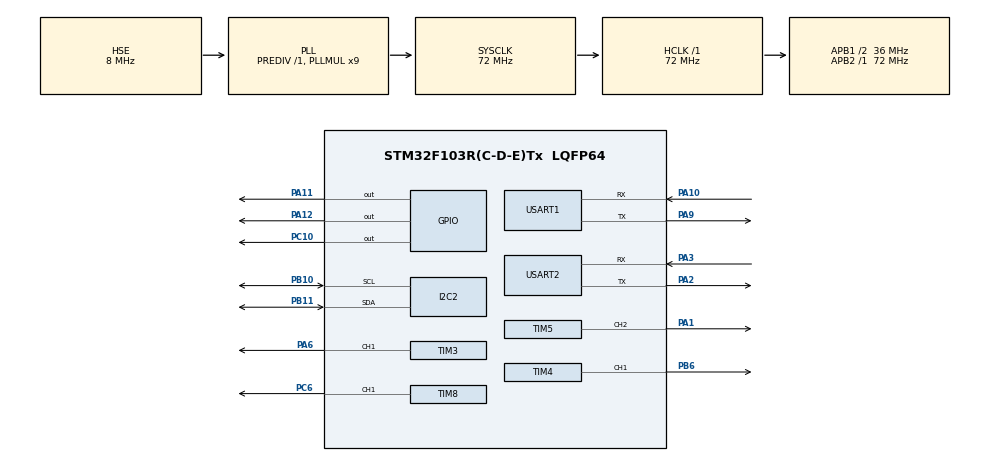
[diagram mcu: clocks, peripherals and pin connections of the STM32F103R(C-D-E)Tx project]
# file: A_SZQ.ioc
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Dma.Request0=USART1_RX
Dma.Request1=USART1_TX
Dma.USART1_RX.0.Direction=DMA_PERIPH_TO_MEMORY
Dma.USART1_RX.0.Instance=DMA1_Channel5
Dma.USART1_RX.0.MemDataAlignment=DMA_MDATAALIGN_BYTE
Dma.USART1_RX.0.MemInc=DMA_MINC_ENABLE
Dma.USART1_RX.0.Mode=DMA_NORMAL
Dma.USART1_RX.0.PeriphDataAlignment=DMA_PDATAALIGN_BYTE
Dma.USART1_RX.0.PeriphInc=DMA_PINC_DISABLE
Dma.USART1_RX.0.Priority=DMA_PRIORITY_LOW
Dma.USART1_TX.1.Direction=DMA_MEMORY_TO_PERIPH
Dma.USART1_TX.1.Instance=DMA1_Channel4
Dma.USART1_TX.1.MemDataAlignment=DMA_MDATAALIGN_BYTE
Dma.USART1_TX.1.MemInc=DMA_MINC_ENABLE
Dma.USART1_TX.1.Mode=DMA_NORMAL
Dma.USART1_TX.1.PeriphDataAlignment=DMA_PDATAALIGN_BYTE
Dma.USART1_TX.1.PeriphInc=DMA_PINC_DISABLE
Dma.USART1_TX.1.Priority=DMA_PRIORITY_LOW
I2C2.I2C_Mode=I2C_Fast
Mcu.Family=STM32F1
Mcu.Name=STM32F103R(C-D-E)Tx
Mcu.Package=LQFP64
NVIC.DMA1_Channel4_IRQn=true\:0\:0\:false\:false\:true\:false\:true\:true
NVIC.DMA1_Channel5_IRQn=true\:0\:0\:false\:false\:true\:false\:true\:true
NVIC.PriorityGroup=NVIC_PRIORITYGROUP_4
NVIC.TIM3_IRQn=true\:0\:0\:false\:false\:true\:true\:true\:true
NVIC.TIM4_IRQn=true\:0\:0\:false\:false\:true\:true\:true\:true
NVIC.TIM8_BRK_IRQn=true\:0\:0\:false\:false\:true\:true\:true\:true
NVIC.TIM8_CC_IRQn=true\:0\:0\:false\:false\:true\:true\:true\:true
NVIC.TIM8_TRG_COM_IRQn=true\:0\:0\:false\:false\:true\:true\:true\:true
NVIC.TIM8_UP_IRQn=true\:0\:0\:false\:false\:true\:true\:true\:true
NVIC.USART1_IRQn=true\:0\:0\:false\:false\:true\:true\:true\:true
PA1.Signal=S_TIM5_CH2
PA10.Mode=Asynchronous
PA10.Signal=USART1_RX
PA11.Signal=GPIO_Output
PA12.Signal=GPIO_Output
PA13.Mode=Serial_Wire
PA13.Signal=SYS_JTMS-SWDIO
PA14.Mode=Serial_Wire
PA14.Signal=SYS_JTCK-SWCLK
PA2.Mode=Asynchronous
PA2.Signal=USART2_TX
PA3.Mode=Asynchronous
PA3.Signal=USART2_RX
PA6.Signal=S_TIM3_CH1
PA9.Mode=Asynchronous
PA9.Signal=USART1_TX
PB10.Mode=I2C
PB10.Signal=I2C2_SCL
PB11.Mode=I2C
PB11.Signal=I2C2_SDA
PB6.Signal=S_TIM4_CH1
PC10.Signal=GPIO_Output
PC6.Signal=S_TIM8_CH1
PD0-OSC_IN.Mode=HSE-External-Oscillator
PD0-OSC_IN.Signal=RCC_OSC_IN
PD1-OSC_OUT.Mode=HSE-External-Oscillator
PD1-OSC_OUT.Signal=RCC_OSC_OUT
ProjectManager.HeapSize=0x200
ProjectManager.StackSize=0x400
ProjectManager.TargetToolchain=MDK-ARM V5.32
RCC.AHBFreq_Value=72000000
RCC.APB1CLKDivider=RCC_HCLK_DIV2
RCC.APB1Freq_Value=36000000
RCC.APB1TimFreq_Value=72000000
RCC.APB2Freq_Value=72000000
RCC.APB2TimFreq_Value=72000000
RCC.HCLKFreq_Value=72000000
RCC.PLLMUL=RCC_PLL_MUL9
RCC.PLLSourceVirtual=RCC_PLLSOURCE_HSE
RCC.SYSCLKFreq_VALUE=72000000
RCC.SYSCLKSource=RCC_SYSCLKSOURCE_PLLCLK
RCC.USBFreq_Value=72000000
SH.S_TIM3_CH1.0=TIM3_CH1,PWM Generation1 CH1
SH.S_TIM4_CH1.0=TIM4_CH1,PWM Generation1 CH1
SH.S_TIM5_CH2.0=TIM5_CH2,PWM Generation2 CH2
SH.S_TIM8_CH1.0=TIM8_CH1,PWM Generation1 CH1
TIM3.Channel-PWM\ Generation1\ CH1=TIM_CHANNEL_1
TIM3.Period=100-1
TIM3.Prescaler=720-1
TIM4.AutoReloadPreload=TIM_AUTORELOAD_PRELOAD_ENABLE
TIM4.Channel-PWM\ Generation1\ CH1=TIM_CHANNEL_1
TIM4.Period=100-1
TIM4.Prescaler=720-1
TIM5.AutoReloadPreload=TIM_AUTORELOAD_PRELOAD_ENABLE
TIM5.Channel-PWM\ Generation2\ CH2=TIM_CHANNEL_2
TIM5.Period=2000-1
TIM5.Prescaler=720-1
TIM8.Channel-PWM\ Generation1\ CH1=TIM_CHANNEL_1
TIM8.Period=100-1
TIM8.Prescaler=720-1
USART1.VirtualMode=VM_ASYNC
USART2.VirtualMode=VM_ASYNC
VP_TIM3_VS_ClockSourceINT.Mode=Internal
VP_TIM4_VS_ClockSourceINT.Mode=Internal
VP_TIM5_VS_ClockSourceINT.Mode=Internal
VP_TIM8_VS_ClockSourceINT.Mode=Internal
board=custom

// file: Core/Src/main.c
/* USER CODE BEGIN Header */
/**
  ******************************************************************************
  * @file           : main.c
  * @brief          : Main program body
  ******************************************************************************
  * @attention
  *
  * Copyright (c) 2025 STMicroelectronics.
  * All rights reserved.
  *
  * This software is licensed under terms that can be found in the LICENSE file
  * in the root directory of this software component.
  * If no LICENSE file comes with this software, it is provided AS-IS.
  *
  ******************************************************************************
  */
/* USER CODE END Header */
#include "main.h"
#include "dma.h"
#include "i2c.h"
#include "tim.h"
#include "usart.h"
#include "gpio.h"

/* USER CODE BEGIN Includes */
#include "headfile.h"

/* USER CODE END Includes */

void SystemClock_Config(void);

int main(void)
{

  /* MCU Configuration--------------------------------------------------------*/

  /* Reset of all peripherals, Initializes the Flash interface and the Systick. */
  HAL_Init();

  /* Configure the system clock */
  SystemClock_Config();

  /* Initialize all configured peripherals */
  MX_GPIO_Init();
  MX_DMA_Init();
  MX_I2C2_Init();
  MX_TIM4_Init();
  MX_USART1_UART_Init();
  MX_USART2_UART_Init();
  MX_TIM3_Init();
  MX_TIM8_Init();
  MX_TIM5_Init();
  /* USER CODE BEGIN 2 */

Usart1_init();
Usart1_ReadData();
OLED_Init();
HAL_TIM_PWM_Start(&htim5, TIM_CHANNEL_2);
BJMotor_Speed(40,25);

  /* USER CODE END 2 */

  /* Infinite loop */
  /* USER CODE BEGIN WHILE */
  while (1)
  {
    lcd_show();

//char text[20];
//      sprintf(text,"12333");
//      Usart1_SendData((uint8_t *)text,3);
      HAL_Delay(400);
    user_uart_process();
    /* USER CODE END WHILE */

  }
}

void SystemClock_Config(void)
{
  RCC_OscInitTypeDef RCC_OscInitStruct = {0};
  RCC_ClkInitTypeDef RCC_ClkInitStruct = {0};

  /** Initializes the RCC Oscillators according to the specified parameters
  * in the RCC_OscInitTypeDef structure.
  */
  RCC_OscInitStruct.OscillatorType = RCC_OSCILLATORTYPE_HSE;
  RCC_OscInitStruct.HSEState = RCC_HSE_ON;
  RCC_OscInitStruct.HSEPredivValue = RCC_HSE_PREDIV_DIV1;
  RCC_OscInitStruct.HSIState = RCC_HSI_ON;
  RCC_OscInitStruct.PLL.PLLState = RCC_PLL_ON;
  RCC_OscInitStruct.PLL.PLLSource = RCC_PLLSOURCE_HSE;
  RCC_OscInitStruct.PLL.PLLMUL = RCC_PLL_MUL9;
  if (HAL_RCC_OscConfig(&RCC_OscInitStruct) != HAL_OK)
  {
    Error_Handler();
  }

  /** Initializes the CPU, AHB and APB buses clocks
  */
  RCC_ClkInitStruct.ClockType = RCC_CLOCKTYPE_HCLK|RCC_CLOCKTYPE_SYSCLK
                              |RCC_CLOCKTYPE_PCLK1|RCC_CLOCKTYPE_PCLK2;
  RCC_ClkInitStruct.SYSCLKSource = RCC_SYSCLKSOURCE_PLLCLK;
  RCC_ClkInitStruct.AHBCLKDivider = RCC_SYSCLK_DIV1;
  RCC_ClkInitStruct.APB1CLKDivider = RCC_HCLK_DIV2;
  RCC_ClkInitStruct.APB2CLKDivider = RCC_HCLK_DIV1;

  if (HAL_RCC_ClockConfig(&RCC_ClkInitStruct, FLASH_LATENCY_2) != HAL_OK)
  {
    Error_Handler();
  }
}

void Error_Handler(void)
{
  __disable_irq();
  while (1)
  {
  }
}
